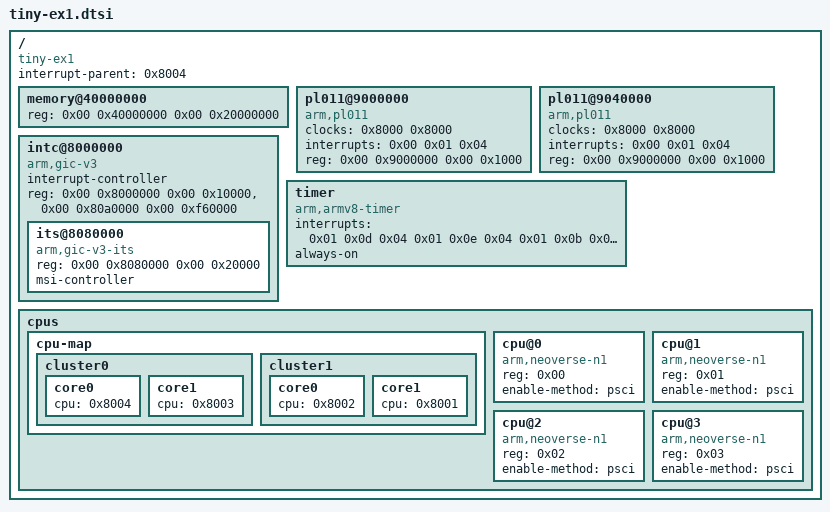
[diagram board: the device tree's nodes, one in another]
//===----------------------------------------------------------------------===//
//
//                                  tinyOS
//
//  This program is free software: you can redistribute it and/or modify
//  it under the terms of the GNU General Public License as published by
//  the Free Software Foundation, either version 3 of the License, or
//  (at your option) any later version.
//
//  This program is distributed in the hope that it will be useful,
//  but WITHOUT ANY WARRANTY; without even the implied warranty of
//  MERCHANTABILITY or FITNESS FOR A PARTICULAR PURPOSE.  See the
//  GNU General Public License for more details.
//
//  You should have received a copy of the GNU General Public License
//  along with this program.  If not, see <http://www.gnu.org/licenses/>.
//
//	Copyright (C) 2024, Harry Moulton <me@h3adsh0tzz.com>
//
//===----------------------------------------------------------------------===//

/**
 * Name:		Tiny EX1
 * Desc:		Tiny Platform Experimental, Variant 1.
 *
 *				This is an Experimental platform, and does not conform to a
 *				particular config as defined in the TinyOS specification.
 *
 *				CPU: 4x ARM Neoverse N1 cores, 2x Clusters (2x2)
 *				RAM: 512MB
 */

/dts-v1/;

/ {
	/* default cell size, if not otherwise specified */
	#size-cells = <0x02>;
	#address-cells = <0x02>;

	/**
	 * The 'interrupt-parent' is the phandle of the cpu where interrupts are
	 * routed to. Ideally, this should be the boot cpu.
	 */
	interrupt-parent = <0x8004>;
	compatible = "tiny-ex1";

	/**
	 * Tiny Platforms have two memory banks: Secure (SRAM) and Non-secure (DRAM),
	 * with SRAM being a fixed size across all platforms, and DRAM being variable.
	 *
	 * This will be read by the kernel when setting up the proper kernel virtual
	 * memory and pagetables.
	 */
	memory@40000000 {
		reg = <0x00 0x40000000 0x00 0x20000000>;
		device_type = "memory";
	};

	/**
	 * On the Experimental platform, both UART interfaces are non-secure so the
	 * kernel can use the second one for mass debug outputs.
	 */
	pl011@9000000 {
		clock-names = "uartclk\0apb_pclk";
		clocks = <0x8000 0x8000>;
		interrupts = <0x00 0x01 0x04>;
		reg = <0x00 0x9000000 0x00 0x1000>;
		compatible = "arm,pl011\0arm,primecell";
	};
	
	pl011@9040000 {
		clock-names = "uartclk\0apb_pclk";
		clocks = <0x8000 0x8000>;
		interrupts = <0x00 0x01 0x04>;
		reg = <0x00 0x9000000 0x00 0x1000>;
		compatible = "arm,pl011\0arm,primecell";
	};

	/**
	 * ARM GICv3 Interrupt Controller
	 */
	intc@8000000 {
		compatible = "arm,gic-v3";
		#interrupt-cells = <0x03>;
		#address-cells = <0x02>;
		#size-cells = <0x02>;
		ranges;
		interrupt-controller;
		reg = 	<0x00 0x8000000 0x00 0x10000>,	// GICD
				<0x00 0x80a0000 0x00 0xf60000>;	// GICR

		its@8080000 {
			phandle = <0x8008>;
			reg = <0x00 0x8080000 0x00 0x20000>;
			#msi-cells = <0x01>;
			msi-controller;
			compatible = "arm,gic-v3-its";
		};
	};

	/**
	 * ARM Generic Virtual Timer
	 */
	timer {
		interrupts = <0x01 0x0d 0x04 0x01 0x0e 0x04 0x01 0x0b 0x04 0x01 0x0a 0x04>;
		always-on;
		compatible = "arm,armv8-timer\0arm,armv7-timer";
	};

	/**
	 * CPU Map. This platform contains four Arm Neoverse N1 cores arranged into
	 * two clusters.
	 */
	cpus {
		#size-cells = <0x00>;
		#address-cells = <0x01>;

		cpu-map {
			cluster0 {
				core0 {
					cpu = <0x8004>;
				};
				core1 {
					cpu = <0x8003>;
				};
			};
			cluster1 {
				core0 {
					cpu = <0x8002>;
				};
				core1 {
					cpu = <0x8001>;
				};
			};
		};

		cpu@0 {
			phandle = <0x8004>;
			reg = <0x00>;
			enable-method = "psci";
			compatible = "arm,neoverse-n1";
			device_type = "cpu";
		};

		cpu@1 {
			phandle = <0x8003>;
			reg = <0x01>;
			enable-method = "psci";
			compatible = "arm,neoverse-n1";
			device_type = "cpu";
		};

		cpu@2 {
			phandle = <0x8002>;
			reg = <0x02>;
			enable-method = "psci";
			compatible = "arm,neoverse-n1";
			device_type = "cpu";
		};

		cpu@3 {
			phandle = <0x8001>;
			reg = <0x03>;
			enable-method = "psci";
			compatible = "arm,neoverse-n1";
			device_type = "cpu";
		};
	};
};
